VERSION ""

NS_ :

BS_:

BU_: XXX

BO_ 278 NEW_MSG_1: 8 XXX
 SG_ NEW_SIGNAL_1 : 59|4@0+ (1,0) [0|255] "" XXX

BO_ 280 NEW_MSG_2: 8 XXX
 SG_ NEW_SIGNAL_1 : 23|16@0- (1,0) [0|255] "" XXX

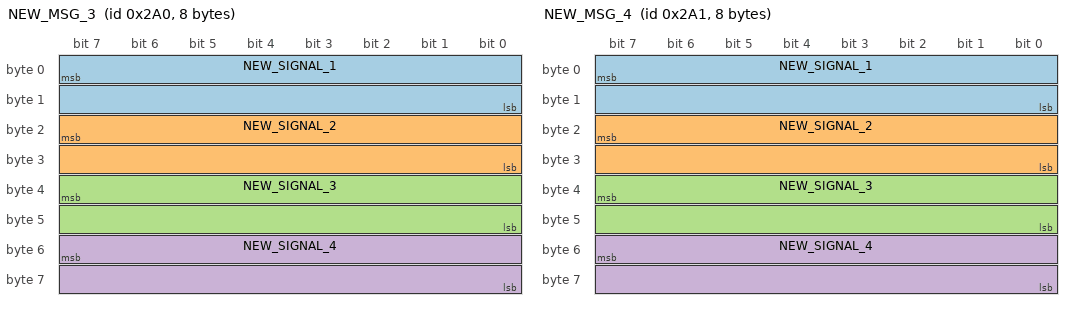
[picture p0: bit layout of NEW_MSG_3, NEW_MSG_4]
BO_ 672 NEW_MSG_3: 8 XXX
 SG_ NEW_SIGNAL_1 : 7|16@0+ (1,0) [0|65535] "" XXX
 SG_ NEW_SIGNAL_2 : 23|16@0+ (1,0) [0|65535] "" XXX
 SG_ NEW_SIGNAL_3 : 39|16@0+ (1,0) [0|65535] "" XXX
 SG_ NEW_SIGNAL_4 : 55|16@0+ (1,0) [0|65535] "" XXX

BO_ 673 NEW_MSG_4: 8 XXX
 SG_ NEW_SIGNAL_1 : 7|16@0+ (1,0) [0|65535] "" XXX
 SG_ NEW_SIGNAL_2 : 23|16@0+ (1,0) [0|65535] "" XXX
 SG_ NEW_SIGNAL_3 : 39|16@0+ (1,0) [0|32767] "" XXX
 SG_ NEW_SIGNAL_4 : 55|16@0+ (1,0) [0|65535] "" XXX

BO_ 792 NEW_MSG_5: 8 XXX
 SG_ NEW_SIGNAL_1 : 39|8@0+ (1,0) [0|255] "" XXX

BO_ 319 NEW_MSG_6: 8 XXX
 SG_ NEW_SIGNAL_1 : 15|16@0+ (1,0) [0|255] "" XXX

BO_ 304 NEW_MSG_7: 8 XXX
 SG_ NEW_SIGNAL_1 : 15|8@0+ (1,0) [0|255] "" XXX

BO_ 384 NEW_MSG_8: 8 XXX
 SG_ NEW_SIGNAL_1 : 15|16@0+ (1,0) [0|255] "" XXX

BO_ 276 NEW_MSG_9: 8 XXX
 SG_ NEW_SIGNAL_2 : 42|3@0+ (1,0) [0|255] "" XXX
 SG_ NEW_SIGNAL_3 : 42|7@0+ (1,0) [0|15] "" XXX

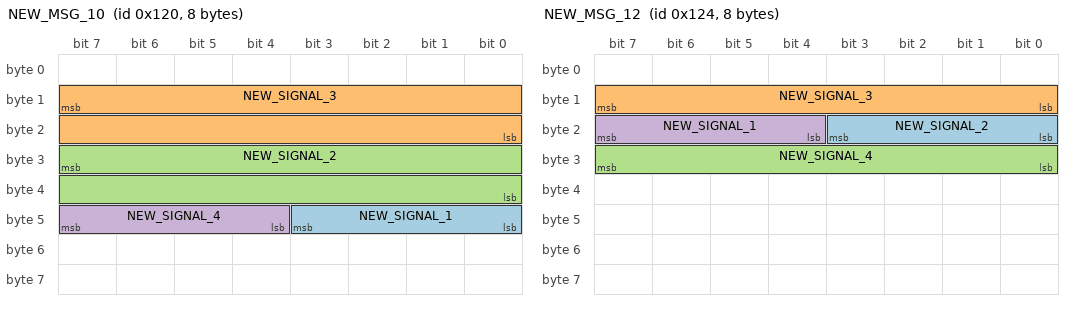
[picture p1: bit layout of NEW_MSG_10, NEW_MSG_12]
BO_ 288 NEW_MSG_10: 8 XXX
 SG_ NEW_SIGNAL_1 : 43|4@0+ (1,0) [0|255] "" XXX
 SG_ NEW_SIGNAL_3 : 15|16@0+ (1,0) [0|255] "" XXX
 SG_ NEW_SIGNAL_2 : 31|16@0+ (1,0) [0|255] "" XXX
 SG_ NEW_SIGNAL_4 : 47|4@0+ (1,0) [0|15] "" XXX

BO_ 290 NEW_MSG_11: 8 XXX
 SG_ NEW_SIGNAL_1 : 39|8@0+ (1,0) [0|255] "" XXX
 SG_ NEW_SIGNAL_2 : 31|8@0+ (1,0) [0|255] "" XXX

BO_ 292 NEW_MSG_12: 8 XXX
 SG_ NEW_SIGNAL_2 : 16|4@1+ (1,0) [0|15] "" XXX
 SG_ NEW_SIGNAL_3 : 8|8@1+ (1,0) [0|15] "" XXX
 SG_ NEW_SIGNAL_4 : 31|8@0+ (1,0) [0|255] "" XXX
 SG_ NEW_SIGNAL_1 : 20|4@1+ (1,0) [0|255] "" XXX

BO_ 977 NEW_MSG_13: 8 XXX
 SG_ NEW_SIGNAL_1 : 31|8@0+ (1,0) [0|255] "" XXX
 SG_ NEW_SIGNAL_2 : 39|8@0+ (1,0) [0|255] "" XXX

BO_ 953 NEW_MSG_14: 8 XXX
 SG_ NEW_SIGNAL_1 : 8|4@1+ (1,0) [0|15] "" XXX
 SG_ NEW_SIGNAL_2 : 24|4@1+ (1,0) [0|15] "" XXX
